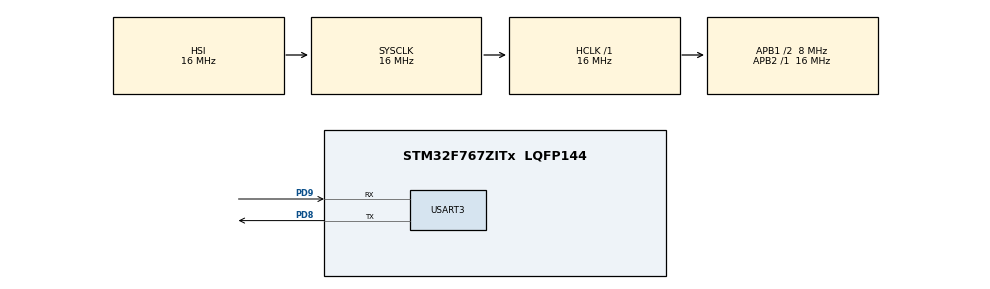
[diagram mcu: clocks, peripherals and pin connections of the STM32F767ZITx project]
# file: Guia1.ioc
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Mcu.Family=STM32F7
Mcu.Name=STM32F767ZITx
Mcu.Package=LQFP144
NVIC.PriorityGroup=NVIC_PRIORITYGROUP_4
NVIC.TIM6_DAC_IRQn=true\:15\:0\:false\:false\:true\:false\:true
NVIC.TimeBase=TIM6_DAC_IRQn
NVIC.TimeBaseIP=TIM6
NVIC.USART3_IRQn=true\:0\:0\:false\:false\:true\:true\:true
PD8.Mode=Asynchronous
PD8.Signal=USART3_TX
PD9.Mode=Asynchronous
PD9.Signal=USART3_RX
ProjectManager.HeapSize=0x200
ProjectManager.StackSize=0x400
ProjectManager.TargetToolchain=STM32CubeIDE
RCC.48MHZClocksFreq_Value=24000000
RCC.AHBFreq_Value=16000000
RCC.APB1CLKDivider=RCC_HCLK_DIV2
RCC.APB1Freq_Value=8000000
RCC.APB1TimFreq_Value=16000000
RCC.APB2Freq_Value=16000000
RCC.APB2TimFreq_Value=16000000
RCC.CortexFreq_Value=16000000
RCC.HCLKFreq_Value=16000000
RCC.HSE_VALUE=16000000
RCC.HSI_VALUE=16000000
RCC.LSE_VALUE=32768
RCC.PLLMUL=RCC_PLL_MUL9
RCC.PRESCALERUSB=RCC_USBCLKSOURCE_PLL_DIV1_5
RCC.SYSCLKFreq_VALUE=16000000
RCC.SYSCLKSourceVirtual=RCC_SYSCLKSOURCE_PLLCLK
RCC.USBFreq_Value=96000000
RCC.VCOOutputFreq_Value=192000000
USART3.VirtualMode-Asynchronous=VM_ASYNC
VP_SYS_VS_tim6.Mode=TIM6
board=NUCLEO-F767ZI

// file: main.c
/* USER CODE BEGIN Header */
/**
  ******************************************************************************
  * @file           : main.c
  * @brief          : Main program body
  ******************************************************************************
  * @attention
  *
  * Copyright (c) 2022 STMicroelectronics.
  * All rights reserved.
  *
  * This software is licensed under terms that can be found in the LICENSE file
  * in the root directory of this software component.
  * If no LICENSE file comes with this software, it is provided AS-IS.
  *
  ******************************************************************************
  */
/* USER CODE END Header */
#include "main.h"
#include "usart.h"
#include "gpio.h"

void SystemClock_Config(void);

int main(void)
{

  /* MCU Configuration--------------------------------------------------------*/

  /* Reset of all peripherals, Initializes the Flash interface and the Systick. */
  HAL_Init();

  /* Configure the system clock */
  SystemClock_Config();

  /* Initialize all configured peripherals */
  MX_GPIO_Init();
  MX_USART3_UART_Init();
  /* USER CODE BEGIN 2 */
  init_UART3();
  	printf("Hello STM32!!\r\n");
  	printf("Type a message and press enter\r\n");
  /* USER CODE END 2 */

  /* Infinite loop */
  while (1)
  {

  }
}

void SystemClock_Config(void)
{
  RCC_OscInitTypeDef RCC_OscInitStruct = {0};
  RCC_ClkInitTypeDef RCC_ClkInitStruct = {0};

  /** Configure the main internal regulator output voltage
  */
  __HAL_RCC_PWR_CLK_ENABLE();
  __HAL_PWR_VOLTAGESCALING_CONFIG(PWR_REGULATOR_VOLTAGE_SCALE3);
  /** Initializes the RCC Oscillators according to the specified parameters
  * in the RCC_OscInitTypeDef structure.
  */
  RCC_OscInitStruct.OscillatorType = RCC_OSCILLATORTYPE_HSI;
  RCC_OscInitStruct.HSIState = RCC_HSI_ON;
  RCC_OscInitStruct.HSICalibrationValue = RCC_HSICALIBRATION_DEFAULT;
  RCC_OscInitStruct.PLL.PLLState = RCC_PLL_NONE;
  if (HAL_RCC_OscConfig(&RCC_OscInitStruct) != HAL_OK)
  {
    Error_Handler();
  }
  /** Initializes the CPU, AHB and APB buses clocks
  */
  RCC_ClkInitStruct.ClockType = RCC_CLOCKTYPE_HCLK|RCC_CLOCKTYPE_SYSCLK
                              |RCC_CLOCKTYPE_PCLK1|RCC_CLOCKTYPE_PCLK2;
  RCC_ClkInitStruct.SYSCLKSource = RCC_SYSCLKSOURCE_HSI;
  RCC_ClkInitStruct.AHBCLKDivider = RCC_SYSCLK_DIV1;
  RCC_ClkInitStruct.APB1CLKDivider = RCC_HCLK_DIV2;
  RCC_ClkInitStruct.APB2CLKDivider = RCC_HCLK_DIV1;

  if (HAL_RCC_ClockConfig(&RCC_ClkInitStruct, FLASH_LATENCY_0) != HAL_OK)
  {
    Error_Handler();
  }
}

void HAL_TIM_PeriodElapsedCallback(TIM_HandleTypeDef *htim)
{
  if (htim->Instance == TIM6) {
    HAL_IncTick();
  }
}

void Error_Handler(void)
{
  __disable_irq();
  while (1)
  {
  }
}
